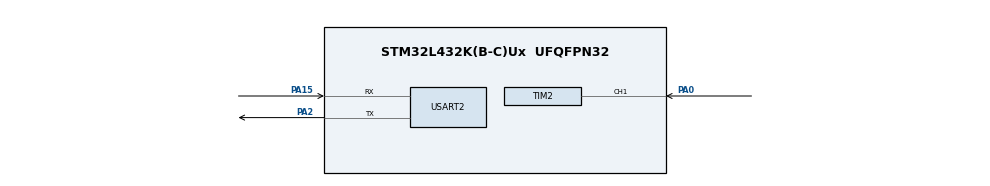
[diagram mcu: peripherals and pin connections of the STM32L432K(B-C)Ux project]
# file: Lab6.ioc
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ADC1.Channel-1\#ChannelRegularConversion=ADC_CHANNEL_VBAT
ADC1.NbrOfConversionFlag=1
ADC1.OffsetNumber-1\#ChannelRegularConversion=ADC_OFFSET_NONE
ADC1.Rank-1\#ChannelRegularConversion=1
ADC1.SamplingTime-1\#ChannelRegularConversion=ADC_SAMPLETIME_2CYCLES_5
ADC1.master=1
Mcu.Family=STM32L4
Mcu.Name=STM32L432K(B-C)Ux
Mcu.Package=UFQFPN32
NVIC.PriorityGroup=NVIC_PRIORITYGROUP_4
PA0.Signal=S_TIM2_CH1
PA15\ (JTDI).Mode=Asynchronous
PA15\ (JTDI).Signal=USART2_RX
PA2.Mode=Asynchronous
PA2.Signal=USART2_TX
ProjectManager.HeapSize=0x200
ProjectManager.StackSize=0x400
ProjectManager.TargetToolchain=STM32CubeIDE
RCC.ADCFreq_Value=32000000
RCC.HSE_VALUE=8000000
RCC.HSI48_VALUE=48000000
RCC.HSI_VALUE=16000000
RCC.LSE_VALUE=32768
RCC.MSI_VALUE=4000000
RCC.PLLSAI1N=16
RCC.USBFreq_Value=32000000
RCC.VCOOutputFreq_Value=32000000
SH.S_TIM2_CH1.0=TIM2_CH1,Input_Capture1_from_TI1
TIM2.Channel-Input_Capture1_from_TI1=TIM_CHANNEL_1
USART2.RxPinLevelInvertParam=ADVFEATURE_RXINV_ENABLE
USART2.TxPinLevelInvertParam=ADVFEATURE_TXINV_ENABLE
USART2.VirtualMode-Asynchronous=VM_ASYNC
VP_ADC1_TempSens_Input.Mode=IN-TempSens
VP_ADC1_Vbat_Input.Mode=IN-Vbat
VP_RTC_VS_RTC_Activate.Mode=RTC_Enabled
VP_RTC_VS_RTC_Calendar.Mode=RTC_Calendar
board=custom

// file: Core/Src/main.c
/* USER CODE BEGIN Header */
/**
  ******************************************************************************
  * @file           : main.c
  * @brief          : Main program body
  ******************************************************************************
  * @attention
  *
  * Copyright (c) 2026 STMicroelectronics.
  * All rights reserved.
  *
  * This software is licensed under terms that can be found in the LICENSE file
  * in the root directory of this software component.
  * If no LICENSE file comes with this software, it is provided AS-IS.
  *
  ******************************************************************************
  */
/* USER CODE END Header */
#include "main.h"

#include <stdio.h>
#include <string.h>
#include "flash.h"
#include "commands.h"
#include "retarget.h"
#include "uart_rx_buffer.h"
#include "stm32l4xx_ll_usart.h"

#include "stm32l4xx_ll_adc.h"
#include "stm32l4xx_ll_bus.h"

#include "stm32l4xx_ll_tim.h"
#include "stm32l4xx_ll_gpio.h"

circ_buf_t g_rxbuf;
static char linebuf[128];
static uint16_t linelen = 0;
uint8_t rxbuf_temp;

ADC_HandleTypeDef hadc1;

RTC_HandleTypeDef hrtc;

TIM_HandleTypeDef htim2;

UART_HandleTypeDef huart2;
//circ_buf_t g_rxbuf;

//static uint8_t linebuf[128];
//static uint16_t linelen = 0;

volatile uint32_t g_period_ticks  = 0;
volatile uint8_t  g_capture_ready = 0;
volatile uint8_t  g_capture_started = 0;
volatile uint32_t g_last_capture = 0;

void SystemClock_Config(void);
static void MX_GPIO_Init(void);
static void MX_ADC1_Init(void);
static void MX_RTC_Init(void);
static void MX_TIM2_Init(void);
static void MX_USART2_UART_Init(void);
void ADC1_Init_Internal(void);
uint16_t ADC1_ReadChannel(uint32_t channel);
static void TIM2_Init_InputCapture(void);
/* USER CODE BEGIN PFP */
static void print_prompt(void);
/* USER CODE END PFP */

extern UART_HandleTypeDef huart2;

//void HAL_UART_RxCpltCallback(UART_HandleTypeDef *huart)
//	{
//	    if (huart->Instance == USART2)
//	    {
//	        rxbuf_push(&g_rxbuf, rxbuf_temp);
//
//	        HAL_UART_Receive_IT(&huart2, &rxbuf_temp, 1);
//	    }
//	}

int main(void)
{

  /* MCU Configuration--------------------------------------------------------*/

  /* Reset of all peripherals, Initializes the Flash interface and the Systick. */
  HAL_Init();

  MX_TIM2_Init();
  HAL_TIM_Base_Start(&htim2);

  /* Configure the system clock */
  SystemClock_Config();

  /* Initialize all configured peripherals */
  MX_GPIO_Init();
  MX_ADC1_Init();
  MX_RTC_Init();
  MX_TIM2_Init();
  MX_USART2_UART_Init();
  //HAL_UART_Receive_IT(&huart2, (uint8_t*)&rxbuf_temp, 1);
  LL_USART_EnableIT_RXNE(USART2);
  NVIC_SetPriority(USART2_IRQn, 0);
  NVIC_EnableIRQ(USART2_IRQn);
  RetargetInit(&huart2);
  rxbuf_init(&g_rxbuf);
  ADC1_Init_Internal();
  TIM2_Init_InputCapture();
  flash_write_log("reset");
  printf("System Up and Running\r\n");
  //printf("> ");
  print_prompt();

  /* Infinite loop */
  /* USER CODE BEGIN WHILE */
  while (1)
  {
	  uint8_t ch;
	  while (rxbuf_pop(&g_rxbuf, &ch) == 0)
	  {
		  if (ch == '\r')
	      {
			  printf("\r\n");
	          if (linelen < 128)
	          {
	        	  linebuf[linelen] = 0;
	          }
	          if (linelen > 0)
	          {
	        	  if (execute_command(linebuf) == 0)
	        	  {
	        		  printf("OK\r\n");
	        	  }
	              else
	              {
	            	  printf("NOK\r\n");
	              }
	          }
	          linelen = 0;
	          //printf("> ");
	          print_prompt();
	          continue;
	      }
	      if (ch == 0x7F || ch == '\b')
	      {
	    	  if (linelen > 0)
	    	  {
	    		  linelen--;
	    		  printf("\b \b");
	    	  }
	          continue;
	      }
	      if (linelen < 127)
	      {
	    	  linebuf[linelen++] = ch;
	    	  printf("%c", ch);
	      }
	  }
  }
  /* USER CODE END WHILE */
  /* USER CODE END 3 */
}

void SystemClock_Config(void)
{
  RCC_OscInitTypeDef RCC_OscInitStruct = {0};
  RCC_ClkInitTypeDef RCC_ClkInitStruct = {0};

  /** Configure the main internal regulator output voltage
  */
  if (HAL_PWREx_ControlVoltageScaling(PWR_REGULATOR_VOLTAGE_SCALE1) != HAL_OK)
  {
    Error_Handler();
  }

  /** Initializes the RCC Oscillators according to the specified parameters
  * in the RCC_OscInitTypeDef structure.
  */
  RCC_OscInitStruct.OscillatorType = RCC_OSCILLATORTYPE_LSI|RCC_OSCILLATORTYPE_MSI;
  RCC_OscInitStruct.LSIState = RCC_LSI_ON;
  RCC_OscInitStruct.MSIState = RCC_MSI_ON;
  RCC_OscInitStruct.MSICalibrationValue = 0;
  RCC_OscInitStruct.MSIClockRange = RCC_MSIRANGE_6;
  RCC_OscInitStruct.PLL.PLLState = RCC_PLL_NONE;
  if (HAL_RCC_OscConfig(&RCC_OscInitStruct) != HAL_OK)
  {
    Error_Handler();
  }

  /** Initializes the CPU, AHB and APB buses clocks
  */
  RCC_ClkInitStruct.ClockType = RCC_CLOCKTYPE_HCLK|RCC_CLOCKTYPE_SYSCLK
                              |RCC_CLOCKTYPE_PCLK1|RCC_CLOCKTYPE_PCLK2;
  RCC_ClkInitStruct.SYSCLKSource = RCC_SYSCLKSOURCE_MSI;
  RCC_ClkInitStruct.AHBCLKDivider = RCC_SYSCLK_DIV1;
  RCC_ClkInitStruct.APB1CLKDivider = RCC_HCLK_DIV1;
  RCC_ClkInitStruct.APB2CLKDivider = RCC_HCLK_DIV1;

  if (HAL_RCC_ClockConfig(&RCC_ClkInitStruct, FLASH_LATENCY_0) != HAL_OK)
  {
    Error_Handler();
  }
}

static void MX_ADC1_Init(void)
{

  ADC_ChannelConfTypeDef sConfig = {0};

  /** Common config
  */
  hadc1.Instance = ADC1;
  hadc1.Init.ClockPrescaler = ADC_CLOCK_ASYNC_DIV1;
  hadc1.Init.Resolution = ADC_RESOLUTION_12B;
  hadc1.Init.DataAlign = ADC_DATAALIGN_RIGHT;
  hadc1.Init.ScanConvMode = ADC_SCAN_DISABLE;
  hadc1.Init.EOCSelection = ADC_EOC_SINGLE_CONV;
  hadc1.Init.LowPowerAutoWait = DISABLE;
  hadc1.Init.ContinuousConvMode = DISABLE;
  hadc1.Init.NbrOfConversion = 1;
  hadc1.Init.DiscontinuousConvMode = DISABLE;
  hadc1.Init.ExternalTrigConv = ADC_SOFTWARE_START;
  hadc1.Init.ExternalTrigConvEdge = ADC_EXTERNALTRIGCONVEDGE_NONE;
  hadc1.Init.DMAContinuousRequests = DISABLE;
  hadc1.Init.Overrun = ADC_OVR_DATA_PRESERVED;
  hadc1.Init.OversamplingMode = DISABLE;
  if (HAL_ADC_Init(&hadc1) != HAL_OK)
  {
    Error_Handler();
  }

  /** Configure Regular Channel
  */
  sConfig.Channel = ADC_CHANNEL_VBAT;
  sConfig.Rank = ADC_REGULAR_RANK_1;
  sConfig.SamplingTime = ADC_SAMPLETIME_2CYCLES_5;
  sConfig.SingleDiff = ADC_SINGLE_ENDED;
  sConfig.OffsetNumber = ADC_OFFSET_NONE;
  sConfig.Offset = 0;
  if (HAL_ADC_ConfigChannel(&hadc1, &sConfig) != HAL_OK)
  {
    Error_Handler();
  }

}

static void MX_RTC_Init(void)
{

  /* USER CODE BEGIN RTC_Init 0 */
	HAL_PWR_EnableBkUpAccess();
  /* USER CODE END RTC_Init 0 */

  RTC_TimeTypeDef sTime = {0};
  RTC_DateTypeDef sDate = {0};

  /** Initialize RTC Only
  */
  hrtc.Instance = RTC;
  hrtc.Init.HourFormat = RTC_HOURFORMAT_24;
  hrtc.Init.AsynchPrediv = 127;
  hrtc.Init.SynchPrediv = 255;
  hrtc.Init.OutPut = RTC_OUTPUT_DISABLE;
  hrtc.Init.OutPutRemap = RTC_OUTPUT_REMAP_NONE;
  hrtc.Init.OutPutPolarity = RTC_OUTPUT_POLARITY_HIGH;
  hrtc.Init.OutPutType = RTC_OUTPUT_TYPE_OPENDRAIN;
  if (HAL_RTC_Init(&hrtc) != HAL_OK)
  {
    Error_Handler();
  }

  if(HAL_RTCEx_BKUPRead(&hrtc, RTC_BKP_DR0) == 0x32F2)
  {
	  return;
  }

  /** Initialize RTC and set the Time and Date
  */
  sTime.Hours = 0x0;
  sTime.Minutes = 0x0;
  sTime.Seconds = 0x0;
  sTime.DayLightSaving = RTC_DAYLIGHTSAVING_NONE;
  sTime.StoreOperation = RTC_STOREOPERATION_RESET;
  if (HAL_RTC_SetTime(&hrtc, &sTime, RTC_FORMAT_BCD) != HAL_OK)
  {
    Error_Handler();
  }
  sDate.WeekDay = RTC_WEEKDAY_MONDAY;
  sDate.Month = RTC_MONTH_JANUARY;
  sDate.Date = 0x1;
  sDate.Year = 0x0;

  if (HAL_RTC_SetDate(&hrtc, &sDate, RTC_FORMAT_BCD) != HAL_OK)
  {
    Error_Handler();
  }
  HAL_RTCEx_BKUPWrite(&hrtc, RTC_BKP_DR0, 0x32F2);

}

static void MX_TIM2_Init(void)
{

  TIM_MasterConfigTypeDef sMasterConfig = {0};
  TIM_IC_InitTypeDef sConfigIC = {0};

  htim2.Instance = TIM2;
  htim2.Init.Prescaler = 0;
  htim2.Init.CounterMode = TIM_COUNTERMODE_UP;
  htim2.Init.Period = 4294967295;
  htim2.Init.ClockDivision = TIM_CLOCKDIVISION_DIV1;
  htim2.Init.AutoReloadPreload = TIM_AUTORELOAD_PRELOAD_DISABLE;
  if (HAL_TIM_IC_Init(&htim2) != HAL_OK)
  {
    Error_Handler();
  }
  sMasterConfig.MasterOutputTrigger = TIM_TRGO_RESET;
  sMasterConfig.MasterSlaveMode = TIM_MASTERSLAVEMODE_DISABLE;
  if (HAL_TIMEx_MasterConfigSynchronization(&htim2, &sMasterConfig) != HAL_OK)
  {
    Error_Handler();
  }
  sConfigIC.ICPolarity = TIM_INPUTCHANNELPOLARITY_RISING;
  sConfigIC.ICSelection = TIM_ICSELECTION_DIRECTTI;
  sConfigIC.ICPrescaler = TIM_ICPSC_DIV1;
  sConfigIC.ICFilter = 0;
  if (HAL_TIM_IC_ConfigChannel(&htim2, &sConfigIC, TIM_CHANNEL_1) != HAL_OK)
  {
    Error_Handler();
  }

}

static void MX_USART2_UART_Init(void)
{

  huart2.Instance = USART2;
  huart2.Init.BaudRate = 115200;
  huart2.Init.WordLength = UART_WORDLENGTH_8B;
  huart2.Init.StopBits = UART_STOPBITS_1;
  huart2.Init.Parity = UART_PARITY_NONE;
  huart2.Init.Mode = UART_MODE_TX_RX;
  huart2.Init.HwFlowCtl = UART_HWCONTROL_NONE;
  huart2.Init.OverSampling = UART_OVERSAMPLING_16;
  huart2.Init.OneBitSampling = UART_ONE_BIT_SAMPLE_DISABLE;
//  huart2.AdvancedInit.AdvFeatureInit = UART_ADVFEATURE_TXINVERT_INIT|UART_ADVFEATURE_RXINVERT_INIT;
//  huart2.AdvancedInit.TxPinLevelInvert = UART_ADVFEATURE_TXINV_ENABLE;
//  huart2.AdvancedInit.RxPinLevelInvert = UART_ADVFEATURE_RXINV_ENABLE;
  huart2.AdvancedInit.AdvFeatureInit = UART_ADVFEATURE_NO_INIT;
  if (HAL_UART_Init(&huart2) != HAL_OK)
  {
    Error_Handler();
  }

}

static void MX_GPIO_Init(void)
{
  /* GPIO Ports Clock Enable */
	__HAL_RCC_GPIOA_CLK_ENABLE();
	__HAL_RCC_GPIOB_CLK_ENABLE();
  /* USER CODE BEGIN MX_GPIO_Init_1 */
	GPIO_InitTypeDef GPIO_InitStruct = {0};
	HAL_GPIO_WritePin(LD3_GPIO_Port, LD3_Pin, GPIO_PIN_RESET);

	GPIO_InitStruct.Pin   = LD3_Pin;
	GPIO_InitStruct.Mode  = GPIO_MODE_OUTPUT_PP;
	GPIO_InitStruct.Pull  = GPIO_NOPULL;
	GPIO_InitStruct.Speed = GPIO_SPEED_FREQ_LOW;
	HAL_GPIO_Init(LD3_GPIO_Port, &GPIO_InitStruct);
  /* USER CODE END MX_GPIO_Init_1 */

}
void ADC1_Init_Internal(void)
{
	//enable ADC clock
	LL_AHB2_GRP1_EnableClock(LL_AHB2_GRP1_PERIPH_ADC);

	//enable: Temp sensor + Vrefint
	LL_ADC_SetCommonPathInternalCh(__LL_ADC_COMMON_INSTANCE(ADC1),
		LL_ADC_PATH_INTERNAL_TEMPSENSOR | LL_ADC_PATH_INTERNAL_VREFINT);

	if (LL_ADC_IsEnabled(ADC1))
	{
		LL_ADC_Disable(ADC1);
		while (LL_ADC_IsEnabled(ADC1));
	}

	//calibrate ADC
	LL_ADC_StartCalibration(ADC1, LL_ADC_SINGLE_ENDED);
	while (LL_ADC_IsCalibrationOnGoing(ADC1));

	//basic configuration
	LL_ADC_REG_SetSequencerLength(ADC1, LL_ADC_REG_SEQ_SCAN_DISABLE);
	LL_ADC_REG_SetContinuousMode(ADC1, LL_ADC_REG_CONV_SINGLE);
	LL_ADC_REG_SetTriggerSource(ADC1, LL_ADC_REG_TRIG_SOFTWARE);

	//enable ADC and wait
	LL_ADC_Enable(ADC1);
	while (!LL_ADC_IsActiveFlag_ADRDY(ADC1));
}
uint16_t ADC1_ReadChannel(uint32_t channel)
{
	LL_ADC_SetChannelSamplingTime(ADC1, channel, LL_ADC_SAMPLINGTIME_247CYCLES_5);

	LL_ADC_REG_SetSequencerRanks(ADC1, LL_ADC_REG_RANK_1, channel);

	LL_ADC_ClearFlag_EOC(ADC1);
	LL_ADC_ClearFlag_EOS(ADC1);

	LL_ADC_REG_StartConversion(ADC1);

	while (!LL_ADC_IsActiveFlag_EOC(ADC1));

	return (uint16_t)LL_ADC_REG_ReadConversionData12(ADC1);
}
static void TIM2_Init_InputCapture(void)
{
	//enable peripheral clocks
	LL_APB1_GRP1_EnableClock(LL_APB1_GRP1_PERIPH_TIM2);
	LL_AHB2_GRP1_EnableClock(LL_AHB2_GRP1_PERIPH_GPIOA);

	//configure alternate function
	LL_GPIO_SetPinMode(GPIOA, LL_GPIO_PIN_5, LL_GPIO_MODE_ALTERNATE);
	LL_GPIO_SetPinPull(GPIOA, LL_GPIO_PIN_5, LL_GPIO_PULL_NO);
	LL_GPIO_SetPinSpeed(GPIOA, LL_GPIO_PIN_5, LL_GPIO_SPEED_FREQ_HIGH);
	LL_GPIO_SetAFPin_0_7(GPIOA, LL_GPIO_PIN_5, LL_GPIO_AF_1);

	//set basic timer settings
	LL_TIM_SetPrescaler(TIM2, 0);                  //full speed (32 MHz)
	LL_TIM_SetCounterMode(TIM2, LL_TIM_COUNTERMODE_UP);
	LL_TIM_SetAutoReload(TIM2, 0xFFFFFFFF);        //max 32-bit range

	//configure input channel capture
	LL_TIM_IC_SetActiveInput(TIM2, LL_TIM_CHANNEL_CH1, LL_TIM_ACTIVEINPUT_DIRECTTI);
	LL_TIM_IC_SetPrescaler(TIM2, LL_TIM_CHANNEL_CH1, LL_TIM_ICPSC_DIV1);
	LL_TIM_IC_SetFilter(TIM2, LL_TIM_CHANNEL_CH1, LL_TIM_IC_FILTER_FDIV1);
	LL_TIM_IC_SetPolarity(TIM2, LL_TIM_CHANNEL_CH1, LL_TIM_IC_POLARITY_RISING);

	//enable input channel
	LL_TIM_CC_EnableChannel(TIM2, LL_TIM_CHANNEL_CH1);

	//enable interrupt for compare channel
	LL_TIM_EnableIT_CC1(TIM2);

	//enable TIM2 interrupt
	NVIC_SetPriority(TIM2_IRQn, 0);
	NVIC_EnableIRQ(TIM2_IRQn);

	//start timer
	LL_TIM_EnableCounter(TIM2);
}
/* USER CODE BEGIN 4 */
static void print_prompt(void)
{
	RTC_TimeTypeDef clk;
	RTC_DateTypeDef dt;
	HAL_RTC_GetTime(&hrtc, &clk, RTC_FORMAT_BIN);
	HAL_RTC_GetDate(&hrtc, &dt, RTC_FORMAT_BIN);
	printf("%02d/%02d/20%02d %02d:%02d:%02d IULS> ",
			dt.Month,
			dt.Date,
			dt.Year,
			clk.Hours,
			clk.Minutes,
			clk.Seconds);
}
/* USER CODE END 4 */

void Error_Handler(void)
{
  __disable_irq();
  while (1)
  {
  }
}
